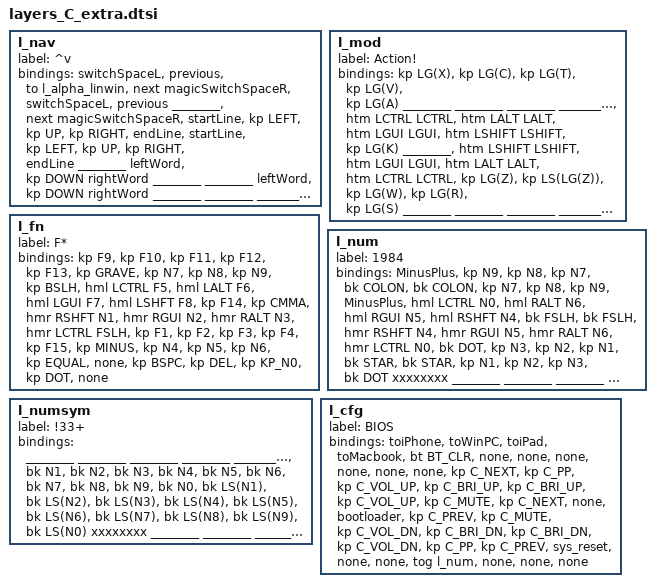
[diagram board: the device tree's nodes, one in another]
//                                     shorcuts & Navigation
//╭────────────────────────────────────────────╮ ╭──────────────────────────────────────────╮
//|  close |   quit  | ScrCp | SelCp |   ESC   | | Zoom+ |  HOME  |   UP   |  PG_UP |       |
//|   ctrl |   alt   |  gui  |  shft |   Find  | | Lword |  LEFT  |  DOWN  |   RGT  | Rword |
//|  undo  |   cut   |  copy |  pste | findAgn | | Zoom- |   END  | Zreset |  PG_DN |  |
//╰──────────────────╮       | mute  |  APPSW  | |  back |  fwd   |        ╭────────────────╯
//                   ╰─────────────────────────╯ ╰─────────────────────────╯
/*
&kp RG(W)       &kp RG(Q)       &kp LG(LS(N4))     &kp LG(LS(LC(N4)))  &kp ESC                         &kp LG(EQUAL)  &kp HOME  &kp UP      &kp PG_UP  &none
&kp LCTRL       &kp LALT        &kp LGUI           &kp LSHFT           &kp RG(F)                       &kp LA(LEFT)   &kp LEFT  &kp DOWN    &kp RIGHT  &kp LA(RIGHT)
&kp RG(Z)       &kp RG(X)       &kp RG(C)          &kp RG(V)           &kp RG(G)                       &kp LG(MINUS)  &kp END   &kp LG(N0)  &kp PG_DN  &none
*/


                l_nav {
                        label = "<^v>";
                        bindings = <
// The key in the middle is temporary, I think eventually I'd like to have "show spaces" there
&switchSpaceL  &previous    &to l_alpha_linwin    &next      magicSwitchSpaceR              &switchSpaceL  &previous   ________    &next      magicSwitchSpaceR
&startLine     &kp LEFT     &kp UP      &kp RIGHT  &endLine                       &startLine     &kp LEFT    &kp UP      &kp RIGHT  &endLine
________       leftWord     &kp DOWN    rightWord  ________                       ________       leftWord    &kp DOWN    rightWord  ________
                                        ________   ________   ________      ________   ________   ________
                        >;
                };


//                                       Symbol & math (for Mac)
//  * left paired symbols are "linger keys" via hold taps. Tap for left, hold for pair with insertion point between
//╭────────────────────────────────────────────╮ ╭──────────────────────────────────────────╮
//|    Z   |    Q    | ScrCp | SelCp |   ESC   | |   ¢   |    $   |    €   |    £   |   ¥   |
//|    <*  |    [$   |   (*  |   {*  |   TAB   | |   ¡   |    *   |    =   |    +   |   /   |
//|    >   |    ]    |   )   |   }   |   RET   | |   _   |    |   |    &   |    ^   |   %   |
//╰──────────────────╮       | dwdlt |  dwdr   | |       |    °   |        ╭────────────────╯
//                   ╰─────────────────────────╯ ╰─────────────────────────╯
                l_mod {
                        label = "Action!";
                        bindings = <

// TODO: Add for linwin (and need extra mod layer for linwin, and changing the layer switch on the base layer)

&kp LG(X)           &kp LG(C)         &kp LG(T)         &kp LG(V)              &kp LG(A)                  ________      ________               ________          ________          ________
&htm LCTRL LCTRL    &htm LALT LALT    &htm LGUI LGUI    &htm LSHIFT LSHIFT     &kp LG(K)                  ________      &htm LSHIFT LSHIFT     &htm LGUI LGUI    &htm LALT LALT    &htm LCTRL LCTRL
&kp LG(Z)           &kp LS(LG(Z))     &kp LG(W)         &kp LG(R)              &kp LG(S)                  ________      ________               ________          ________          ________
// undo             redo
                                                        ________      ________      ________            ________      ________      ________

/*
// Old Bindings
&kp Z           &kp Q              &kp LG(LS(N4))     &kp LG(LS(LC(N4)))  &kp ESC                     &kp RA(N4)  &kp DLLR        &kp LA(LS(N2))  &kp LA(N3)     &kp RA(Y)
&lk_ltgt GT LT  &lk_bkt RBKT LBKT  &lk_par RPAR LPAR  &lk_brc RBRC LBRC   &kp TAB                     &kp LA(N1)  &mt RSHFT STAR  &mt RGUI EQUAL  &mt RALT PLUS  &mt LCTRL FSLH
&kp GT          &kp RBKT           &kp RPAR           &kp RBRC            &kp RETURN                  &kp MINUS   &kp PIPE        &kp AMPS        &kp CARET      &kp PRCNT
                                                        &none   &kp LA(BSPC)   &kp LA(DEL)     &none &kp LA(N0)  &none 
*/

                        >;
                };

//                                         Fkey & Num Row (optimized)
//╭────────────────────────────────────────────╮ ╭───────────────────────────────────────╮
//|    F9   |  F10   |  F11   |  F12   |  F13  | |   `   |   7   |   8   |   9   |   \   |
//|   C/F5  |  A/F6  |  G/F7  |  S/F8  |  F14  | |   ,   |  S/1  |  G/2  |  A/3  |  C//  |
//|    F1   |   F2   |   F3   |   F4   |  F15  | |   -   |   4   |   5   |   6   |   =   |
//╰──────────────────╮        |  BKSP  |   DEL | |   0   |   .   |       ╭───────────────╯
//                   ╰─────────────────────────╯ ╰───────────────────────╯

                l_fn {
                        label = "F*";
                        bindings = <

&kp F9         &kp F10       &kp F11       &kp F12        &kp F13                    &kp GRAVE  &kp N7         &kp N8        &kp N9        &kp BSLH
&hml LCTRL F5  &hml LALT F6  &hml LGUI F7  &hml LSHFT F8  &kp F14                    &kp CMMA   &hmr RSHFT N1  &hmr RGUI N2  &hmr RALT N3  &hmr LCTRL FSLH
&kp F1         &kp F2        &kp F3        &kp F4         &kp F15                    &kp MINUS  &kp N4         &kp N5        &kp N6        &kp EQUAL
                                        &none   &kp BSPC     &kp DEL       &kp KP_N0    &kp DOT &none 

                        >;
                };


//                                          Nav & NumPad (standard)
//╭────────────────────────────────────────────╮ ╭────────────────────────────────────────╮
//|   ESC  |  HOME  |   UP   |  PG_UP |  NUM   | |    /   |   7   |   8   |   9   |   -   |
//|  Lword |  LEFT  |  DOWN  |   RGT  | Rword  | |    *   |  S/4  |  G/5  |  A/6  |  C/+  |
//|   DEL  |  END   |  TAB   |  PG_DN |  SPC   | |    ,   |   1   |   2   |   3   |   =   |
//╰─────────────────╮        |  BKSP  | ENTER  | |    0   |   .   |       ╭───────────────╯
//                  ╰──────────────────────────╯ ╰────────────────────────╯
                l_num {
                        label = "1984"; //
                        bindings = <
/* TODO: Add symbols on this layer */
&MinusPlus     &kp N9        &kp N8       &kp N7        &bk COLON                        &bk COLON    &kp N7        &kp N8       &kp N9       &MinusPlus
&hml LCTRL N0  &hml RALT N6  &hml RGUI N5 &hml RSHFT N4 &bk FSLH                         &bk FSLH     &hmr RSHFT N4 &hmr RGUI N5 &hmr RALT N6 &hmr LCTRL N0
&bk DOT        &kp N3        &kp N2       &kp N1        &bk STAR                         &bk STAR     &kp N1        &kp N2       &kp N3       &bk DOT
                                        xxxxxxxx  ________  ________      ________  ________  xxxxxxxx
                        >;
                };

                l_numsym {
                        label = "!33+"; //
                        bindings = <
/* TODO: Add symbols on this layer */
________       ________      ________     ________      ________                         ________     ________      ________     ________     ________
&bk N1         &bk N2        &bk N3       &bk N4        &bk N5                           &bk N6       &bk N7        &bk N8       &bk N9       &bk N0 
&bk LS(N1)     &bk LS(N2)    &bk LS(N3)   &bk LS(N4)    &bk LS(N5)                       &bk LS(N6)   &bk LS(N7)    &bk LS(N8)   &bk LS(N9)   &bk LS(N0) 
                                        xxxxxxxx  ________  ________      ________  ________  xxxxxxxx
                        >;
                };


                l_cfg {
                        label = "BIOS";
                        bindings = <

&toiPhone     &toWinPC      &toiPad       &toMacbook    &bt BT_CLR                &none         &none         &none       &none       &none
&none         &kp C_NEXT    &kp C_PP      &kp C_VOL_UP  &kp C_BRI_UP              &kp C_BRI_UP  &kp C_VOL_UP  &kp C_MUTE  &kp C_NEXT  &none
&bootloader   &kp C_PREV    &kp C_MUTE    &kp C_VOL_DN  &kp C_BRI_DN              &kp C_BRI_DN  &kp C_VOL_DN  &kp C_PP    &kp C_PREV  &sys_reset
                                                &none  &none  &tog l_num      &none  &none  &none 

                        >;
                };
